# NUC100DN_v1 register map
File version: 1.0
Registers are 32-bit, read-write, reset 0x0 unless marked. A register's access mark holds for its fields unless they carry their own. Offsets are from the block's base; [hi:lo] are bit positions; {n}, {i} and the like mark numbered series.

## PDMA_GCR — PDMA Register Map
Base 0x50008F00
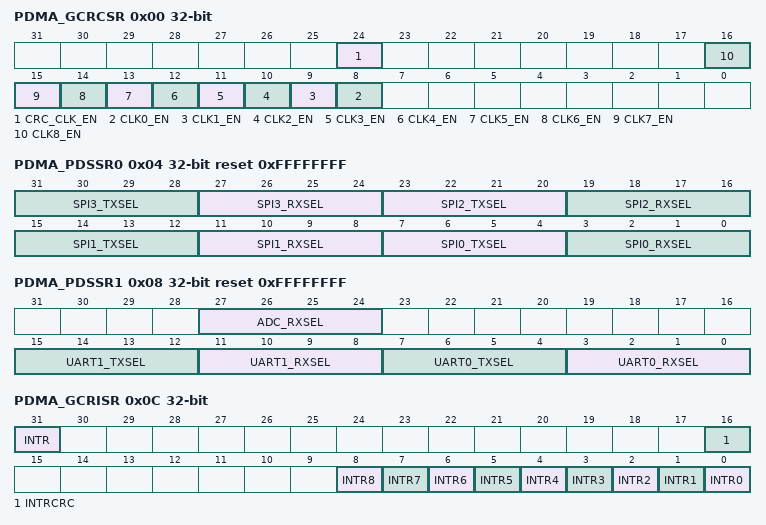
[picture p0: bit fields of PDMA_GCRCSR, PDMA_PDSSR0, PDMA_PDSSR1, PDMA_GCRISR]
0x00 PDMA_GCRCSR — PDMA Global Control Register
  [24] CRC_CLK_EN — CRC Controller Clock Enable Control
    0=CRC controller clock Disabled; 1=CRC controller clock Enabled
  [n+8] CLK{n}_EN (n=0..8) — PDMA Controller Channel {n} Clock Enable Control
    0=PDMA channel {n} clock Disabled; 1=PDMA channel {n} clock Enabled
0x04 PDMA_PDSSR0 reset 0xFFFFFFFF — PDMA Service Selection Control Register 0
  [8n+7:8n+4] SPI{n}_TXSEL (n=0..3) — PDMA SPI{n} TX Selection. This field defines which PDMA channel is connected to the on-chip peripheral SPI{n} TX. Software can configure the TX channel setting by SPI{n}_TXSEL. The channel configuration is the same as SPI0_RXSEL field. Please refer to the explanation of SPI0_RXSEL.
  [27:24] SPI3_RXSEL — PDMA SPI3 RX Selection. This field defines which PDMA channel is connected to the on-chip peripheral SPI3 RX. Software can configure the RX channel setting by SPI3_RXSEL. The channel configuration is the same as SPI0_RXSEL field. Please refer to the explanation of SPI0_RXSEL.
  [19:16] SPI2_RXSEL — PDMA SPI2 RX Selection. This field defines which PDMA channel is connected to the on-chip peripheral SPI2 RX. Software can configure the RX channel setting by SPI2_RXSEL. The channel configuration is the same as SPI0_RXSEL field. Please refer to the explanation of SPI0_RXSEL.
  [11:8] SPI1_RXSEL — PDMA SPI1 RX Selection. This field defines which PDMA channel is connected to the on-chip peripheral SPI1 RX. Software can configure the RX channel setting by SPI1_RXSEL. The channel configuration is the same as SPI0_RXSEL field. Please refer to the explanation of SPI0_RXSEL.
  [3:0] SPI0_RXSEL — PDMA SPI0 RX Selection. This field defines which PDMA channel is connected to the on-chip peripheral SPI0 RX. Software can change the channel RX setting by SPI0_RXSEL. 4'b0000: CH0. 4'b0001: CH1. 4'b0010: CH2. 4'b0011: CH3. 4'b0100: CH4. 4'b0101: CH5. 4'b0110: CH6. 4'b0111: CH7. 4'b1000: CH8. Others : Reserved
0x08 PDMA_PDSSR1 reset 0xFFFFFFFF — PDMA Service Selection Control Register 1
  [27:24] ADC_RXSEL — PDMA ADC RX Selection. This field defines which PDMA channel is connected to the on-chip peripheral ADC RX. Software can configure the RX channel setting by ADC_RXSEL. The channel configuration is the same as UART0_RXSEL field. Please refer to the explanation of UART0_RXSEL
  [15:12] UART1_TXSEL — PDMA UART1 TX Selection. This field defines which PDMA channel is connected to the on-chip peripheral UART1 TX. Software can configure the TX channel setting by UART1_TXSEL. The channel configuration is the same as UART0_RXSEL field. Please refer to the explanation of UART0_RXSEL
  [11:8] UART1_RXSEL — PDMA UART1 RX Selection. This field defines which PDMA channel is connected to the on-chip peripheral UART1 RX. Software can configure the RX channel setting by UART1_RXSEL. The channel configuration is the same as UART0_RXSEL field. Please refer to the explanation of UART0_RXSEL
  [7:4] UART0_TXSEL — PDMA UART0 TX Selection. This field defines which PDMA channel is connected to the on-chip peripheral UART0 TX. Software can configure the TX channel setting by UART0_TXSEL. The channel configuration is the same as UART0_RXSEL field. Please refer to the explanation of UART0_RXSEL
  [3:0] UART0_RXSEL — PDMA UART0 RX Selection. This field defines which PDMA channel is connected to the on-chip peripheral UART0 RX. Software can change the channel RX setting by UART0_RXSEL. 4'b0000: CH0. 4'b0001: CH1. 4'b0010: CH2. 4'b0011: CH3. 4'b0100: CH4. 4'b0101: CH5. 4'b0110: CH6. 4'b0111: CH7. 4'b1000: CH8. Others : Reserved
0x0C PDMA_GCRISR ro — PDMA Global Interrupt Status Register
  [31] INTR — Interrupt Status (Read Only). This bit is the interrupt status of PDMA controller.
  [16] INTRCRC — Interrupt Status of CRC Controller (Read Only). This bit is the interrupt status of CRC controller
  [n] INTR{n} (n=0..8) — Interrupt Status of Channel {n} (Read Only). This bit is the interrupt status of PDMA channel{n}.
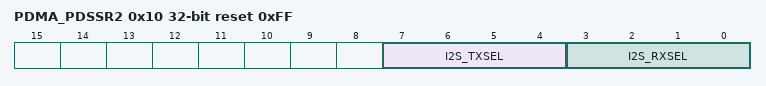
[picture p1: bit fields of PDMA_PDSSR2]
0x10 PDMA_PDSSR2 reset 0xFF — PDMA Service Selection Control Register 2
  [7:4] I2S_TXSEL — PDMA I2S TX Selection. This field defines which PDMA channel is connected to the on-chip peripheral I2S TX. Software can configure the TX channel setting by I2S_TXSEL. The channel configuration is the same as I2S_RXSEL field. Please refer to the explanation of I2S_RXSEL.
  [3:0] I2S_RXSEL — PDMA I2S RX Selection. This field defines which PDMA channel is connected to the on-chip peripheral I2S RX. Software can change the channel RX setting by I2S_RXSEL. 4'b0000: CH0. 4'b0001: CH1. 4'b0010: CH2. 4'b0011: CH3. 4'b0100: CH4. 4'b0101: CH5. 4'b0110: CH6. 4'b0111: CH7. 4'b1000: CH8. Others : Reserved
